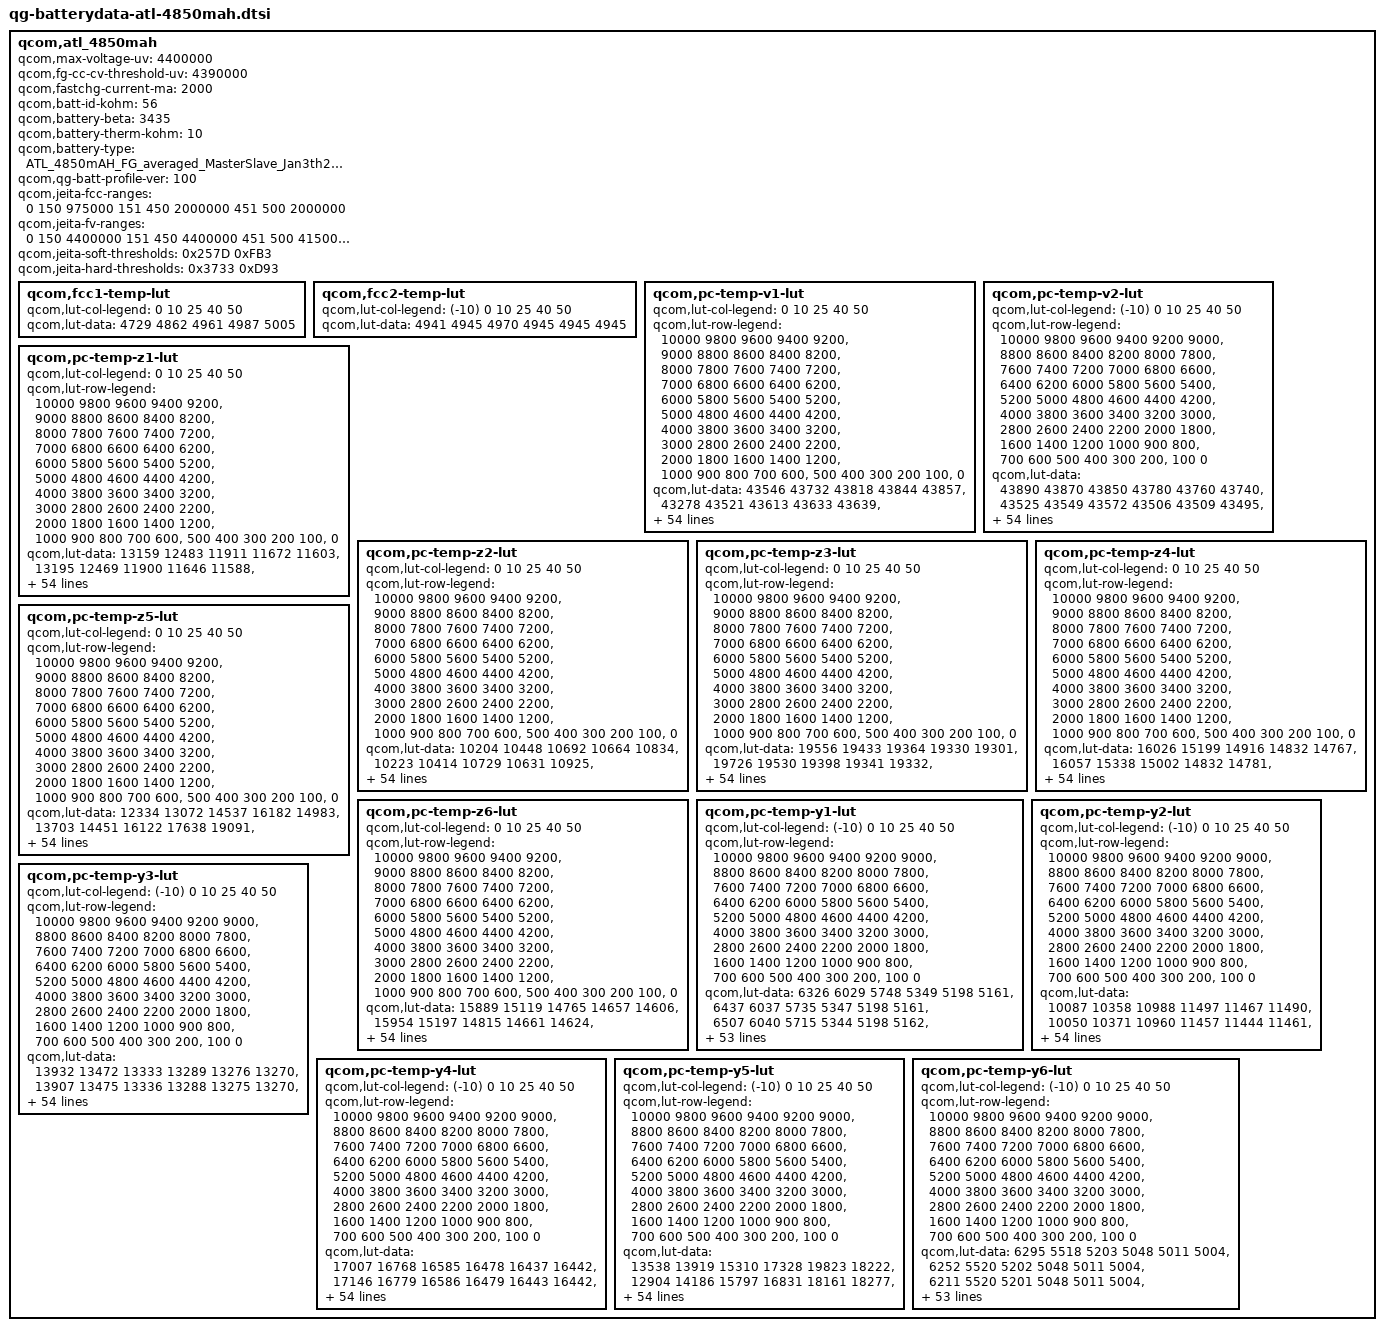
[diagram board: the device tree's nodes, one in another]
/* Copyright (c) 2018, The Linux Foundation. All rights reserved.
 *
 * This program is free software; you can redistribute it and/or modify
 * it under the terms of the GNU General Public License version 2 and
 * only version 2 as published by the Free Software Foundation.
 *
 * This program is distributed in the hope that it will be useful,
 * but WITHOUT ANY WARRANTY; without even the implied warranty of
 * MERCHANTABILITY or FITNESS FOR A PARTICULAR PURPOSE.  See the
 * GNU General Public License for more details.
 */

qcom,atl_4850mah {
    /* 3756981_LC_P400_ATL_4850mAH_FG_averaged_MasterSlave_Jan3th2019 */
    qcom,max-voltage-uv = <4400000>;
    qcom,fg-cc-cv-threshold-uv = <4390000>;
    qcom,fastchg-current-ma = <2000>;
    qcom,batt-id-kohm = <56>;
    qcom,battery-beta = <3435>;
    qcom,battery-therm-kohm = <10>;
    qcom,battery-type = "ATL_4850mAH_FG_averaged_MasterSlave_Jan3th2019";
    qcom,qg-batt-profile-ver = <100>;

	qcom,jeita-fcc-ranges = <0   150   975000
				151  450  2000000
				451  500  2000000>;
	qcom,jeita-fv-ranges =  <0   150  4400000
				151  450  4400000
				451  500  4150000>;

	/* COOL = 15 DegC, WARM = 45 DegC */
	qcom,jeita-soft-thresholds = <0x257D 0xFB3>;
	/* COLD = 0 DegC, HOT = 50 DegC */
	qcom,jeita-hard-thresholds = <0x3733 0xD93>;

	qcom,fcc1-temp-lut {
		qcom,lut-col-legend = <0 10 25 40 50>;
		qcom,lut-data = <4729 4862 4961 4987 5005>;
	};

	qcom,fcc2-temp-lut {
		qcom,lut-col-legend = <(-10) 0 10 25 40 50>;
		qcom,lut-data = <4941 4945 4970 4945 4945 4945>;
	};

	qcom,pc-temp-v1-lut {
		qcom,lut-col-legend = <0 10 25 40 50>;
		qcom,lut-row-legend = <10000 9800 9600 9400 9200>,
			<9000 8800 8600 8400 8200>,
			<8000 7800 7600 7400 7200>,
			<7000 6800 6600 6400 6200>,
			<6000 5800 5600 5400 5200>,
			<5000 4800 4600 4400 4200>,
			<4000 3800 3600 3400 3200>,
			<3000 2800 2600 2400 2200>,
			<2000 1800 1600 1400 1200>,
			<1000 900 800 700 600>,
			<500 400 300 200 100>,
			<0>;
		qcom,lut-data = <43546 43732 43818 43844 43857>,
			<43278 43521 43613 43633 43639>,
			<43030 43266 43386 43419 43438>,
			<42794 43019 43149 43197 43217>,
			<42564 42782 42912 42970 42990>,
			<42335 42546 42674 42734 42760>,
			<42109 42312 42437 42497 42528>,
			<41888 42080 42201 42265 42297>,
			<41669 41855 41969 42036 42066>,
			<41460 41633 41741 41809 41837>,
			<41273 41420 41515 41580 41609>,
			<41092 41223 41299 41357 41385>,
			<40884 41034 41097 41141 41166>,
			<40636 40827 40900 40932 40953>,
			<40395 40590 40690 40726 40746>,
			<40186 40361 40470 40523 40544>,
			<39993 40167 40267 40328 40349>,
			<39830 39990 40084 40145 40166>,
			<39696 39832 39912 39971 39990>,
			<39572 39698 39757 39806 39820>,
			<39444 39559 39614 39653 39662>,
			<39318 39391 39431 39474 39486>,
			<39191 39207 39153 39212 39247>,
			<39062 39021 38904 38960 39003>,
			<38935 38818 38770 38814 38844>,
			<38813 38655 38670 38711 38728>,
			<38694 38559 38579 38613 38621>,
			<38589 38488 38496 38515 38515>,
			<38494 38425 38419 38424 38417>,
			<38411 38370 38346 38338 38326>,
			<38351 38322 38279 38258 38243>,
			<38304 38276 38218 38188 38170>,
			<38265 38233 38162 38126 38107>,
			<38230 38195 38112 38070 38046>,
			<38200 38161 38071 38021 37988>,
			<38168 38126 38032 37975 37931>,
			<38136 38092 37993 37925 37869>,
			<38098 38054 37954 37873 37805>,
			<38040 37999 37900 37809 37733>,
			<37960 37908 37811 37723 37649>,
			<37865 37801 37701 37622 37553>,
			<37748 37681 37587 37513 37445>,
			<37613 37544 37458 37389 37319>,
			<37449 37387 37306 37238 37169>,
			<37317 37248 37165 37094 37026>,
			<37224 37154 37072 36998 36936>,
			<37195 37127 37047 36973 36911>,
			<37182 37111 37032 36956 36892>,
			<37154 37089 37014 36938 36875>,
			<37106 37044 36966 36902 36832>,
			<36893 36810 36729 36715 36615>,
			<36462 36384 36306 36328 36217>,
			<35905 35821 35745 35808 35691>,
			<35148 35053 34981 35116 34986>,
			<33972 33862 33814 34112 33949>,
			<30000 30000 30000 30000 30000>;
	};

	qcom,pc-temp-v2-lut {
		qcom,lut-col-legend = <(-10) 0 10 25 40 50>;
		qcom,lut-row-legend = <10000 9800 9600 9400 9200 9000>,
			<8800 8600 8400 8200 8000 7800>,
			<7600 7400 7200 7000 6800 6600>,
			<6400 6200 6000 5800 5600 5400>,
			<5200 5000 4800 4600 4400 4200>,
			<4000 3800 3600 3400 3200 3000>,
			<2800 2600 2400 2200 2000 1800>,
			<1600 1400 1200 1000 900 800>,
			<700 600 500 400 300 200>,
			<100 0>;
		qcom,lut-data = <43890 43870 43850 43780 43760 43740>,
			<43525 43549 43572 43506 43509 43495>,
			<43187 43249 43306 43243 43263 43255>,
			<42878 42974 43052 42993 43023 43018>,
			<42593 42723 42811 42756 42790 42787>,
			<42340 42477 42573 42521 42557 42555>,
			<42131 42228 42335 42287 42325 42323>,
			<41932 41987 42099 42054 42093 42091>,
			<41683 41766 41869 41826 41865 41862>,
			<41394 41559 41643 41602 41638 41635>,
			<41176 41352 41421 41381 41414 41412>,
			<41057 41140 41204 41162 41194 41194>,
			<40937 40930 40992 40947 40978 40980>,
			<40691 40741 40797 40744 40774 40774>,
			<40311 40562 40610 40548 40576 40572>,
			<39980 40333 40400 40349 40378 40376>,
			<39707 39994 40158 40137 40174 40183>,
			<39471 39671 39916 39938 39981 39998>,
			<39282 39469 39691 39778 39816 39830>,
			<39122 39309 39476 39636 39664 39669>,
			<38963 39145 39275 39450 39477 39479>,
			<38807 38977 39085 39190 39236 39242>,
			<38658 38819 38916 38951 39010 39019>,
			<38508 38677 38768 38784 38836 38843>,
			<38367 38545 38634 38645 38686 38689>,
			<38263 38408 38509 38523 38559 38562>,
			<38183 38260 38392 38416 38451 38454>,
			<38116 38142 38289 38319 38352 38355>,
			<38057 38065 38201 38229 38260 38262>,
			<38005 38004 38119 38146 38175 38175>,
			<37954 37953 38034 38072 38099 38097>,
			<37906 37912 37951 38003 38029 38026>,
			<37857 37871 37884 37939 37963 37959>,
			<37805 37828 37831 37876 37904 37899>,
			<37751 37784 37785 37816 37843 37837>,
			<37697 37739 37745 37754 37763 37747>,
			<37641 37694 37708 37690 37667 37628>,
			<37581 37642 37664 37624 37574 37520>,
			<37515 37581 37610 37554 37490 37427>,
			<37444 37512 37545 37480 37408 37341>,
			<37369 37433 37466 37404 37332 37263>,
			<37288 37339 37368 37319 37253 37186>,
			<37208 37230 37244 37211 37148 37081>,
			<37129 37112 37116 37077 37022 36954>,
			<37047 36994 36966 36931 36880 36818>,
			<36945 36884 36900 36880 36830 36774>,
			<36893 36841 36871 36869 36821 36761>,
			<36844 36797 36847 36852 36805 36747>,
			<36773 36747 36813 36825 36780 36726>,
			<36666 36670 36747 36763 36735 36673>,
			<36466 36509 36543 36550 36560 36463>,
			<36109 36149 36104 36110 36163 36052>,
			<35557 35597 35486 35524 35621 35500>,
			<34764 34800 34641 34732 34893 34767>,
			<33502 33572 33347 33535 33833 33689>,
			<30045 30824 29724 30182 32088 31980>;
	};

	qcom,pc-temp-z1-lut {
		qcom,lut-col-legend = <0 10 25 40 50>;
		qcom,lut-row-legend = <10000 9800 9600 9400 9200>,
			<9000 8800 8600 8400 8200>,
			<8000 7800 7600 7400 7200>,
			<7000 6800 6600 6400 6200>,
			<6000 5800 5600 5400 5200>,
			<5000 4800 4600 4400 4200>,
			<4000 3800 3600 3400 3200>,
			<3000 2800 2600 2400 2200>,
			<2000 1800 1600 1400 1200>,
			<1000 900 800 700 600>,
			<500 400 300 200 100>,
			<0>;
		qcom,lut-data = <13159 12483 11911 11672 11603>,
			<13195 12469 11900 11646 11588>,
			<13195 12465 11887 11641 11585>,
			<13186 12460 11870 11635 11581>,
			<13181 12453 11859 11630 11579>,
			<13187 12445 11852 11627 11576>,
			<13195 12431 11846 11624 11574>,
			<13193 12413 11840 11621 11573>,
			<13177 12408 11834 11619 11573>,
			<13167 12408 11832 11618 11573>,
			<13169 12407 11831 11619 11573>,
			<13173 12400 11831 11619 11574>,
			<13168 12384 11831 11619 11575>,
			<13127 12368 11832 11619 11576>,
			<13086 12348 11831 11619 11576>,
			<13071 12336 11830 11619 11576>,
			<13060 12338 11829 11618 11575>,
			<13059 12344 11830 11618 11575>,
			<13076 12351 11830 11618 11576>,
			<13093 12361 11832 11618 11576>,
			<13084 12368 11836 11621 11577>,
			<13055 12369 11839 11623 11578>,
			<13043 12369 11843 11624 11578>,
			<13057 12371 11847 11625 11579>,
			<13074 12377 11850 11627 11581>,
			<13078 12384 11853 11630 11583>,
			<13078 12388 11857 11633 11585>,
			<13079 12393 11863 11635 11588>,
			<13092 12398 11868 11637 11590>,
			<13109 12404 11874 11640 11593>,
			<13111 12411 11879 11644 11595>,
			<13107 12414 11883 11647 11597>,
			<13103 12418 11886 11650 11599>,
			<13107 12422 11890 11653 11601>,
			<13114 12426 11895 11656 11603>,
			<13119 12431 11900 11658 11605>,
			<13122 12437 11907 11661 11607>,
			<13125 12443 11914 11663 11610>,
			<13130 12451 11918 11665 11611>,
			<13136 12461 11919 11668 11613>,
			<13137 12468 11921 11670 11613>,
			<13130 12471 11925 11673 11615>,
			<13128 12472 11933 11676 11616>,
			<13149 12470 11937 11679 11619>,
			<13113 12473 11943 11681 11620>,
			<13170 12496 11947 11685 11621>,
			<13145 12484 11951 11686 11622>,
			<13157 12489 11952 11688 11623>,
			<13081 12501 11947 11689 11624>,
			<13093 12486 11954 11689 11625>,
			<13101 12521 11969 11693 11628>,
			<13112 12531 11972 11698 11633>,
			<13131 12538 11989 11708 11641>,
			<13225 12554 12072 11724 11654>,
			<13225 12554 12072 11724 11654>,
			<13225 12554 12072 11724 11654>;
	};

	qcom,pc-temp-z2-lut {
		qcom,lut-col-legend = <0 10 25 40 50>;
		qcom,lut-row-legend = <10000 9800 9600 9400 9200>,
			<9000 8800 8600 8400 8200>,
			<8000 7800 7600 7400 7200>,
			<7000 6800 6600 6400 6200>,
			<6000 5800 5600 5400 5200>,
			<5000 4800 4600 4400 4200>,
			<4000 3800 3600 3400 3200>,
			<3000 2800 2600 2400 2200>,
			<2000 1800 1600 1400 1200>,
			<1000 900 800 700 600>,
			<500 400 300 200 100>,
			<0>;
		qcom,lut-data = <10204 10448 10692 10664 10834>,
			<10223 10414 10729 10631 10925>,
			<10243 10386 10730 10919 10782>,
			<10263 10366 10700 10936 10924>,
			<10284 10352 10672 10939 11021>,
			<10308 10339 10641 10938 10994>,
			<10329 10323 10622 10936 10940>,
			<10330 10307 10619 10900 10894>,
			<10324 10298 10618 10808 10851>,
			<10316 10292 10618 10778 10797>,
			<10306 10289 10623 10812 10700>,
			<10294 10288 10631 10840 10621>,
			<10274 10288 10648 10837 10631>,
			<10233 10289 10665 10823 10674>,
			<10202 10299 10663 10793 10702>,
			<10198 10315 10652 10708 10715>,
			<10196 10337 10647 10656 10727>,
			<10197 10367 10664 10679 10739>,
			<10219 10397 10690 10720 10752>,
			<10240 10431 10712 10742 10778>,
			<10237 10457 10733 10757 10829>,
			<10226 10469 10739 10774 10857>,
			<10220 10477 10730 10802 10801>,
			<10219 10484 10718 10825 10724>,
			<10218 10491 10707 10815 10746>,
			<10220 10495 10695 10782 10874>,
			<10229 10497 10697 10771 10988>,
			<10238 10499 10726 10786 11082>,
			<10247 10498 10753 10813 11142>,
			<10256 10493 10766 10864 11080>,
			<10261 10488 10774 10931 10908>,
			<10264 10489 10775 10938 10793>,
			<10268 10490 10771 10885 10715>,
			<10273 10495 10769 10850 10677>,
			<10280 10511 10771 10863 10698>,
			<10290 10528 10776 10891 10749>,
			<10304 10536 10784 10921 10818>,
			<10321 10543 10801 10959 10926>,
			<10338 10551 10821 10996 10978>,
			<10355 10562 10851 11032 10977>,
			<10376 10571 10874 11061 10977>,
			<10397 10577 10874 11079 10980>,
			<10427 10583 10869 11090 10988>,
			<10479 10597 10864 11004 10962>,
			<10815 10713 10877 10957 10953>,
			<10922 10841 10971 11030 10989>,
			<10893 10830 10950 11037 10993>,
			<10789 10935 10981 10998 10991>,
			<10786 10956 10977 10978 10945>,
			<10767 11011 11013 11036 11179>,
			<10801 11037 11161 11181 10983>,
			<10657 11051 11145 11005 10711>,
			<10458 11013 11160 10963 10749>,
			<10162 10815 11138 10834 10720>,
			<10162 10815 11138 10834 10720>,
			<10162 10815 11138 10834 10720>;
	};

	qcom,pc-temp-z3-lut {
		qcom,lut-col-legend = <0 10 25 40 50>;
		qcom,lut-row-legend = <10000 9800 9600 9400 9200>,
			<9000 8800 8600 8400 8200>,
			<8000 7800 7600 7400 7200>,
			<7000 6800 6600 6400 6200>,
			<6000 5800 5600 5400 5200>,
			<5000 4800 4600 4400 4200>,
			<4000 3800 3600 3400 3200>,
			<3000 2800 2600 2400 2200>,
			<2000 1800 1600 1400 1200>,
			<1000 900 800 700 600>,
			<500 400 300 200 100>,
			<0>;
		qcom,lut-data = <19556 19433 19364 19330 19301>,
			<19726 19530 19398 19341 19332>,
			<19751 19580 19419 19366 19332>,
			<19756 19595 19431 19369 19344>,
			<19757 19599 19435 19373 19354>,
			<19734 19601 19436 19380 19357>,
			<19700 19603 19436 19384 19358>,
			<19688 19604 19437 19382 19358>,
			<19681 19604 19438 19375 19357>,
			<19678 19593 19437 19370 19355>,
			<19677 19580 19430 19368 19351>,
			<19676 19573 19422 19366 19346>,
			<19678 19566 19413 19363 19341>,
			<19698 19561 19405 19361 19337>,
			<19714 19558 19405 19357 19333>,
			<19708 19555 19409 19348 19331>,
			<19691 19542 19410 19343 19330>,
			<19673 19523 19405 19343 19328>,
			<19647 19511 19399 19343 19325>,
			<19628 19504 19398 19341 19323>,
			<19632 19500 19397 19337 19322>,
			<19649 19513 19398 19335 19320>,
			<19669 19539 19410 19340 19318>,
			<19693 19549 19421 19346 19316>,
			<19716 19552 19417 19342 19312>,
			<19725 19553 19408 19330 19308>,
			<19730 19552 19402 19326 19307>,
			<19732 19548 19399 19331 19329>,
			<19731 19545 19398 19338 19351>,
			<19729 19540 19401 19349 19352>,
			<19725 19535 19407 19362 19352>,
			<19714 19531 19411 19365 19350>,
			<19702 19528 19415 19362 19342>,
			<19691 19525 19416 19358 19334>,
			<19680 19523 19414 19353 19331>,
			<19668 19520 19411 19348 19329>,
			<19656 19515 19407 19346 19329>,
			<19646 19510 19403 19345 19328>,
			<19641 19505 19400 19344 19328>,
			<19638 19501 19398 19342 19326>,
			<19633 19498 19397 19342 19323>,
			<19615 19497 19395 19341 19323>,
			<19598 19495 19391 19340 19322>,
			<19589 19488 19386 19338 19320>,
			<19508 19461 19376 19331 19319>,
			<19466 19437 19369 19328 19313>,
			<19447 19433 19367 19325 19311>,
			<19317 19403 19353 19321 19312>,
			<19313 19403 19351 19321 19308>,
			<19309 19400 19348 19317 19298>,
			<19317 19400 19337 19311 19314>,
			<19316 19383 19324 19319 19325>,
			<19323 19338 19322 19318 19314>,
			<19329 19333 19319 19324 19312>,
			<19329 19333 19319 19324 19312>,
			<19329 19333 19319 19324 19312>;
	};

	qcom,pc-temp-z4-lut {
		qcom,lut-col-legend = <0 10 25 40 50>;
		qcom,lut-row-legend = <10000 9800 9600 9400 9200>,
			<9000 8800 8600 8400 8200>,
			<8000 7800 7600 7400 7200>,
			<7000 6800 6600 6400 6200>,
			<6000 5800 5600 5400 5200>,
			<5000 4800 4600 4400 4200>,
			<4000 3800 3600 3400 3200>,
			<3000 2800 2600 2400 2200>,
			<2000 1800 1600 1400 1200>,
			<1000 900 800 700 600>,
			<500 400 300 200 100>,
			<0>;
		qcom,lut-data = <16026 15199 14916 14832 14767>,
			<16057 15338 15002 14832 14781>,
			<16009 15264 14994 14855 14807>,
			<15833 15186 14938 14829 14792>,
			<15675 15095 14893 14802 14775>,
			<15574 15011 14855 14779 14759>,
			<15487 14949 14822 14759 14743>,
			<15409 14897 14795 14745 14729>,
			<15341 14861 14771 14735 14718>,
			<15279 14834 14751 14724 14708>,
			<15222 14813 14734 14711 14700>,
			<15171 14793 14722 14699 14694>,
			<15128 14775 14717 14690 14688>,
			<15090 14764 14713 14683 14684>,
			<15058 14757 14709 14680 14679>,
			<15031 14752 14703 14680 14672>,
			<15008 14748 14697 14679 14666>,
			<14989 14746 14688 14670 14659>,
			<14974 14740 14680 14658 14653>,
			<14958 14726 14674 14657 14652>,
			<14928 14716 14670 14658 14653>,
			<14883 14716 14674 14662 14654>,
			<14844 14716 14736 14718 14704>,
			<14807 14722 14790 14779 14770>,
			<14780 14766 14790 14784 14778>,
			<14777 14800 14787 14783 14775>,
			<14777 14795 14782 14781 14769>,
			<14777 14784 14771 14765 14736>,
			<14780 14773 14757 14743 14698>,
			<14784 14763 14741 14718 14682>,
			<14784 14752 14723 14692 14672>,
			<14781 14742 14709 14679 14666>,
			<14778 14732 14697 14672 14661>,
			<14775 14723 14690 14668 14659>,
			<14771 14715 14687 14667 14659>,
			<14768 14709 14685 14666 14658>,
			<14764 14704 14684 14667 14659>,
			<14759 14699 14682 14671 14666>,
			<14750 14699 14682 14675 14672>,
			<14739 14702 14687 14682 14678>,
			<14735 14704 14692 14687 14683>,
			<14738 14700 14689 14684 14680>,
			<14739 14694 14683 14675 14673>,
			<14723 14692 14683 14678 14676>,
			<14724 14683 14678 14677 14675>,
			<14731 14672 14655 14660 14661>,
			<14752 14670 14651 14655 14656>,
			<14892 14696 14654 14646 14640>,
			<14889 14689 14648 14630 14628>,
			<14885 14689 14650 14630 14631>,
			<14875 14693 14678 14658 14638>,
			<14895 14721 14698 14657 14636>,
			<14901 14780 14703 14659 14647>,
			<14913 14794 14707 14654 14648>,
			<14913 14794 14707 14654 14648>,
			<14913 14794 14707 14654 14648>;
	};

	qcom,pc-temp-z5-lut {
		qcom,lut-col-legend = <0 10 25 40 50>;
		qcom,lut-row-legend = <10000 9800 9600 9400 9200>,
			<9000 8800 8600 8400 8200>,
			<8000 7800 7600 7400 7200>,
			<7000 6800 6600 6400 6200>,
			<6000 5800 5600 5400 5200>,
			<5000 4800 4600 4400 4200>,
			<4000 3800 3600 3400 3200>,
			<3000 2800 2600 2400 2200>,
			<2000 1800 1600 1400 1200>,
			<1000 900 800 700 600>,
			<500 400 300 200 100>,
			<0>;
		qcom,lut-data = <12334 13072 14537 16182 14983>,
			<13703 14451 16122 17638 19091>,
			<14086 15751 16917 19065 17988>,
			<14259 16545 17527 19156 19262>,
			<14312 16964 17982 19337 20357>,
			<14314 17379 18294 20322 20699>,
			<14316 18155 18649 21287 20917>,
			<14347 19089 19267 21036 21023>,
			<14495 19507 20019 20175 21080>,
			<14666 19630 20648 19937 21157>,
			<14794 19764 21254 20749 21349>,
			<14934 20078 21510 21787 21515>,
			<15195 20605 21050 22625 21434>,
			<15784 21369 20445 23354 21190>,
			<16200 22837 20553 23248 21144>,
			<16129 23839 21335 21671 21661>,
			<15914 22893 22243 20636 22472>,
			<15693 20986 23150 22232 23607>,
			<15414 20525 24310 24653 24985>,
			<15214 21176 25936 25226 25766>,
			<15554 22461 28333 25337 26288>,
			<16899 31858 32351 25590 26494>,
			<18826 47923 42607 27668 25105>,
			<22724 52013 50310 29850 22508>,
			<27674 51824 45424 27661 19977>,
			<31966 51448 34272 21089 17142>,
			<36191 48668 28530 18631 16194>,
			<39048 43301 25504 18522 18374>,
			<40729 39535 24205 18478 21576>,
			<41825 36523 24851 20231 24388>,
			<41535 34944 26450 24460 27085>,
			<38750 34816 28879 27721 27739>,
			<35546 34754 33247 30409 27573>,
			<33024 34848 36667 32326 27446>,
			<30672 35518 38739 33560 29539>,
			<29018 36005 40045 34367 33039>,
			<27654 35801 39769 34429 33658>,
			<26896 35305 38222 34212 33468>,
			<27835 34716 36659 33784 33081>,
			<30145 33833 35300 31128 29459>,
			<30873 33321 33943 28027 24902>,
			<28325 33747 32709 27243 23793>,
			<27052 34231 31392 26858 23345>,
			<30100 32416 28490 24774 21938>,
			<25102 30006 27193 23395 21517>,
			<20681 27928 29321 24400 21102>,
			<19350 26586 28192 23276 20571>,
			<12461 18931 22374 23125 23053>,
			<12394 19245 22060 26559 25040>,
			<12392 19076 21681 25139 20585>,
			<12645 19416 17699 17955 20893>,
			<12433 16375 15306 17613 21564>,
			<12338 13458 14723 16830 17428>,
			<12189 13023 14264 17361 16332>,
			<12189 13023 14264 17361 16332>,
			<12189 13023 14264 17361 16332>;
	};

	qcom,pc-temp-z6-lut {
		qcom,lut-col-legend = <0 10 25 40 50>;
		qcom,lut-row-legend = <10000 9800 9600 9400 9200>,
			<9000 8800 8600 8400 8200>,
			<8000 7800 7600 7400 7200>,
			<7000 6800 6600 6400 6200>,
			<6000 5800 5600 5400 5200>,
			<5000 4800 4600 4400 4200>,
			<4000 3800 3600 3400 3200>,
			<3000 2800 2600 2400 2200>,
			<2000 1800 1600 1400 1200>,
			<1000 900 800 700 600>,
			<500 400 300 200 100>,
			<0>;
		qcom,lut-data = <15889 15119 14765 14657 14606>,
			<15954 15197 14815 14661 14624>,
			<15933 15183 14815 14682 14636>,
			<15838 15162 14796 14673 14635>,
			<15745 15116 14778 14664 14634>,
			<15674 15068 14760 14657 14630>,
			<15610 15036 14745 14650 14623>,
			<15560 15010 14733 14643 14617>,
			<15520 14986 14722 14635 14611>,
			<15486 14965 14712 14627 14606>,
			<15455 14947 14701 14620 14600>,
			<15428 14932 14691 14614 14595>,
			<15407 14920 14684 14609 14590>,
			<15390 14910 14678 14604 14585>,
			<15373 14900 14675 14600 14581>,
			<15353 14891 14674 14596 14577>,
			<15331 14881 14673 14592 14573>,
			<15310 14871 14666 14587 14569>,
			<15290 14862 14659 14582 14565>,
			<15273 14854 14656 14581 14563>,
			<15260 14850 14655 14580 14563>,
			<15249 14855 14657 14580 14562>,
			<15245 14869 14691 14607 14582>,
			<15246 14885 14720 14637 14610>,
			<15248 14906 14719 14638 14612>,
			<15250 14919 14714 14633 14610>,
			<15252 14917 14709 14628 14607>,
			<15255 14912 14704 14624 14604>,
			<15258 14907 14699 14620 14600>,
			<15260 14902 14694 14616 14596>,
			<15259 14897 14690 14612 14592>,
			<15253 14891 14687 14608 14587>,
			<15246 14887 14685 14604 14581>,
			<15242 14883 14683 14600 14576>,
			<15237 14881 14681 14597 14574>,
			<15233 14878 14680 14594 14573>,
			<15228 14875 14678 14594 14573>,
			<15224 14872 14676 14595 14576>,
			<15222 14872 14675 14596 14578>,
			<15220 14874 14677 14599 14579>,
			<15216 14876 14679 14601 14580>,
			<15208 14877 14678 14599 14579>,
			<15200 14877 14675 14596 14576>,
			<15196 14876 14673 14595 14576>,
			<15159 14862 14668 14593 14576>,
			<15144 14849 14656 14584 14567>,
			<15142 14846 14653 14581 14563>,
			<15134 14843 14648 14575 14557>,
			<15130 14840 14644 14568 14550>,
			<15133 14842 14645 14566 14546>,
			<15141 14848 14653 14575 14558>,
			<15156 14856 14657 14581 14564>,
			<15174 14869 14662 14584 14566>,
			<15204 14886 14669 14587 14568>,
			<15204 14886 14669 14587 14568>,
			<15204 14886 14669 14587 14568>;
	};

	qcom,pc-temp-y1-lut {
		qcom,lut-col-legend = <(-10) 0 10 25 40 50>;
		qcom,lut-row-legend = <10000 9800 9600 9400 9200 9000>,
			<8800 8600 8400 8200 8000 7800>,
			<7600 7400 7200 7000 6800 6600>,
			<6400 6200 6000 5800 5600 5400>,
			<5200 5000 4800 4600 4400 4200>,
			<4000 3800 3600 3400 3200 3000>,
			<2800 2600 2400 2200 2000 1800>,
			<1600 1400 1200 1000 900 800>,
			<700 600 500 400 300 200>,
			<100 0>;
		qcom,lut-data = <6326 6029 5748 5349 5198 5161>,
			<6437 6037 5735 5347 5198 5161>,
			<6507 6040 5715 5344 5198 5162>,
			<6545 6040 5693 5342 5197 5162>,
			<6562 6037 5676 5339 5196 5162>,
			<6565 6033 5668 5337 5195 5162>,
			<6531 6024 5666 5334 5193 5161>,
			<6488 6015 5665 5331 5191 5160>,
			<6484 6016 5663 5330 5191 5159>,
			<6487 6026 5661 5329 5191 5159>,
			<6491 6030 5658 5328 5192 5159>,
			<6499 6019 5654 5325 5191 5158>,
			<6507 6007 5650 5323 5189 5157>,
			<6510 6007 5647 5322 5188 5157>,
			<6513 6010 5645 5321 5188 5157>,
			<6512 6015 5643 5321 5188 5157>,
			<6500 6031 5640 5322 5189 5158>,
			<6489 6043 5639 5324 5189 5159>,
			<6495 6038 5640 5324 5189 5159>,
			<6507 6028 5642 5324 5189 5159>,
			<6508 6025 5643 5325 5189 5159>,
			<6495 6031 5643 5328 5189 5159>,
			<6485 6036 5643 5331 5190 5158>,
			<6490 6034 5646 5334 5191 5159>,
			<6500 6030 5651 5337 5193 5162>,
			<6502 6030 5655 5340 5195 5162>,
			<6499 6037 5658 5344 5195 5163>,
			<6496 6042 5662 5347 5196 5163>,
			<6494 6043 5673 5351 5199 5165>,
			<6493 6043 5681 5354 5203 5168>,
			<6488 6048 5682 5358 5205 5170>,
			<6473 6062 5682 5363 5206 5171>,
			<6465 6068 5683 5367 5208 5173>,
			<6473 6046 5690 5370 5211 5174>,
			<6483 6021 5695 5374 5215 5176>,
			<6484 6022 5693 5377 5217 5178>,
			<6483 6034 5689 5380 5220 5180>,
			<6482 6038 5688 5383 5222 5181>,
			<6468 6035 5690 5390 5223 5182>,
			<6452 6031 5693 5395 5224 5183>,
			<6459 6041 5707 5395 5225 5184>,
			<6474 6059 5718 5394 5225 5185>,
			<6476 6042 5710 5401 5227 5185>,
			<6490 6030 5709 5407 5228 5186>,
			<6501 6051 5715 5412 5232 5190>,
			<6464 6029 5716 5411 5233 5192>,
			<6458 6053 5718 5425 5236 5191>,
			<6527 6042 5713 5418 5235 5191>,
			<6474 6075 5740 5426 5237 5193>,
			<6532 6077 5735 5423 5237 5193>,
			<6488 6032 5723 5435 5237 5194>,
			<6533 6076 5724 5436 5241 5198>,
			<6624 6088 5730 5457 5249 5203>,
			<6618 6126 5756 5472 5260 5211>,
			<6618 6126 5756 5472 5260 5211>,
			<6618 6126 5756 5472 5260 5211>;
	};

	qcom,pc-temp-y2-lut {
		qcom,lut-col-legend = <(-10) 0 10 25 40 50>;
		qcom,lut-row-legend = <10000 9800 9600 9400 9200 9000>,
			<8800 8600 8400 8200 8000 7800>,
			<7600 7400 7200 7000 6800 6600>,
			<6400 6200 6000 5800 5600 5400>,
			<5200 5000 4800 4600 4400 4200>,
			<4000 3800 3600 3400 3200 3000>,
			<2800 2600 2400 2200 2000 1800>,
			<1600 1400 1200 1000 900 800>,
			<700 600 500 400 300 200>,
			<100 0>;
		qcom,lut-data = <10087 10358 10988 11497 11467 11490>,
			<10050 10371 10960 11457 11444 11461>,
			<10040 10388 10933 11408 11422 11426>,
			<10052 10407 10907 11358 11401 11391>,
			<10078 10429 10885 11318 11383 11363>,
			<10114 10453 10870 11296 11369 11347>,
			<10161 10487 10857 11288 11358 11341>,
			<10228 10516 10849 11282 11350 11336>,
			<10358 10512 10854 11269 11364 11317>,
			<10580 10490 10871 11250 11410 11279>,
			<10667 10488 10878 11243 11430 11266>,
			<10583 10672 10876 11255 11406 11322>,
			<10493 10866 10874 11267 11369 11381>,
			<10528 10878 10904 11262 11329 11357>,
			<10658 10876 10987 11248 11284 11284>,
			<10772 10874 11059 11248 11278 11261>,
			<10877 10873 11129 11316 11392 11297>,
			<10942 10873 11168 11401 11545 11362>,
			<10642 10890 11158 11460 11683 11503>,
			<9972 10936 11142 11509 11814 11702>,
			<9745 10986 11145 11512 11837 11740>,
			<9715 11048 11180 11458 11771 11637>,
			<9700 11100 11213 11417 11689 11546>,
			<9691 11132 11229 11427 11608 11522>,
			<9685 11155 11242 11452 11535 11507>,
			<9681 11156 11265 11478 11530 11513>,
			<9678 11143 11299 11507 11574 11560>,
			<9676 11134 11319 11539 11621 11619>,
			<9674 11133 11327 11579 11651 11674>,
			<9672 11133 11332 11614 11680 11738>,
			<9671 11127 11334 11623 11718 11831>,
			<9669 11097 11335 11627 11765 11964>,
			<9667 11036 11335 11628 11805 12022>,
			<9666 10529 11331 11620 11839 11998>,
			<9665 9926 11324 11606 11861 11951>,
			<9664 9777 11308 11583 11851 11859>,
			<9663 9711 11281 11548 11805 11700>,
			<9663 9687 11253 11528 11753 11642>,
			<9662 9680 11224 11521 11681 11676>,
			<9661 9676 11194 11516 11629 11709>,
			<9661 9672 11165 11512 11653 11671>,
			<9661 9668 11128 11508 11701 11600>,
			<9660 9665 11060 11491 11680 11617>,
			<9660 9662 10999 11464 11674 11702>,
			<9659 9662 10631 11401 11690 11707>,
			<9659 9660 10822 11394 11521 11517>,
			<9658 9659 10779 11399 11569 11423>,
			<9658 9658 10730 11387 11479 11368>,
			<9658 9658 10688 11367 11530 11464>,
			<9658 9657 10657 11365 11511 11379>,
			<9656 9657 10584 11325 11471 11323>,
			<9654 9656 10159 11239 11370 11272>,
			<9653 9655 9683 11164 11348 11196>,
			<9651 9653 9670 11064 11241 11042>,
			<9651 9653 9670 11064 11241 11042>,
			<9651 9653 9670 11064 11241 11042>;
	};

	qcom,pc-temp-y3-lut {
		qcom,lut-col-legend = <(-10) 0 10 25 40 50>;
		qcom,lut-row-legend = <10000 9800 9600 9400 9200 9000>,
			<8800 8600 8400 8200 8000 7800>,
			<7600 7400 7200 7000 6800 6600>,
			<6400 6200 6000 5800 5600 5400>,
			<5200 5000 4800 4600 4400 4200>,
			<4000 3800 3600 3400 3200 3000>,
			<2800 2600 2400 2200 2000 1800>,
			<1600 1400 1200 1000 900 800>,
			<700 600 500 400 300 200>,
			<100 0>;
		qcom,lut-data = <13932 13472 13333 13289 13276 13270>,
			<13907 13475 13336 13288 13275 13270>,
			<13857 13477 13340 13287 13274 13271>,
			<13799 13477 13343 13287 13274 13272>,
			<13753 13476 13346 13287 13275 13272>,
			<13736 13474 13348 13287 13275 13273>,
			<13738 13469 13349 13287 13278 13274>,
			<13740 13465 13349 13288 13281 13275>,
			<13725 13469 13350 13290 13282 13275>,
			<13666 13486 13350 13294 13283 13275>,
			<13605 13493 13350 13296 13283 13276>,
			<13540 13472 13349 13297 13283 13278>,
			<13494 13446 13347 13297 13283 13280>,
			<13497 13435 13349 13299 13283 13281>,
			<13513 13427 13352 13302 13283 13281>,
			<13516 13422 13352 13302 13283 13281>,
			<13480 13419 13350 13300 13284 13279>,
			<13439 13415 13346 13298 13285 13278>,
			<13420 13406 13342 13300 13285 13280>,
			<13407 13392 13338 13303 13286 13283>,
			<13405 13383 13333 13303 13286 13284>,
			<13413 13377 13329 13297 13283 13280>,
			<13419 13371 13325 13292 13280 13276>,
			<13411 13364 13324 13289 13278 13273>,
			<13396 13356 13322 13287 13277 13271>,
			<13389 13348 13320 13287 13276 13271>,
			<13385 13341 13316 13287 13276 13273>,
			<13384 13335 13314 13288 13276 13274>,
			<13397 13331 13316 13289 13276 13273>,
			<13422 13328 13317 13290 13276 13272>,
			<13444 13329 13317 13290 13276 13272>,
			<13465 13334 13315 13292 13276 13272>,
			<13487 13338 13314 13292 13277 13273>,
			<13510 13339 13313 13292 13278 13273>,
			<13535 13341 13313 13291 13278 13274>,
			<13565 13343 13314 13291 13278 13274>,
			<13599 13344 13317 13290 13277 13273>,
			<13636 13348 13319 13289 13276 13272>,
			<13679 13362 13320 13288 13276 13271>,
			<13724 13386 13321 13287 13275 13271>,
			<13761 13416 13322 13288 13276 13272>,
			<13796 13456 13323 13289 13276 13273>,
			<13846 13508 13321 13290 13276 13274>,
			<13901 13571 13322 13289 13276 13273>,
			<13879 13567 13307 13284 13273 13271>,
			<13940 13656 13326 13287 13275 13273>,
			<14007 13727 13328 13291 13279 13274>,
			<14079 13797 13336 13293 13279 13277>,
			<14148 13867 13344 13297 13281 13282>,
			<14239 13931 13354 13300 13286 13283>,
			<14427 13994 13360 13299 13282 13279>,
			<14742 14072 13359 13297 13281 13276>,
			<15342 14274 13386 13303 13284 13278>,
			<16418 14696 13524 13310 13285 13283>,
			<16418 14696 13524 13310 13285 13283>,
			<16418 14696 13524 13310 13285 13283>;
	};

	qcom,pc-temp-y4-lut {
		qcom,lut-col-legend = <(-10) 0 10 25 40 50>;
		qcom,lut-row-legend = <10000 9800 9600 9400 9200 9000>,
			<8800 8600 8400 8200 8000 7800>,
			<7600 7400 7200 7000 6800 6600>,
			<6400 6200 6000 5800 5600 5400>,
			<5200 5000 4800 4600 4400 4200>,
			<4000 3800 3600 3400 3200 3000>,
			<2800 2600 2400 2200 2000 1800>,
			<1600 1400 1200 1000 900 800>,
			<700 600 500 400 300 200>,
			<100 0>;
		qcom,lut-data = <17007 16768 16585 16478 16437 16442>,
			<17146 16779 16586 16479 16443 16442>,
			<17230 16798 16586 16480 16447 16441>,
			<17272 16820 16586 16481 16450 16441>,
			<17287 16837 16586 16483 16451 16441>,
			<17288 16843 16586 16485 16452 16441>,
			<17226 16843 16585 16488 16450 16442>,
			<17149 16841 16583 16491 16448 16444>,
			<17143 16835 16585 16491 16448 16446>,
			<17156 16818 16592 16491 16452 16450>,
			<17184 16813 16601 16492 16456 16452>,
			<17352 16873 16609 16497 16462 16453>,
			<17522 16953 16622 16506 16468 16454>,
			<17428 17001 16657 16516 16476 16457>,
			<17127 17040 16711 16528 16484 16464>,
			<16963 17037 16725 16542 16492 16472>,
			<16902 16868 16714 16560 16500 16480>,
			<16872 16717 16696 16578 16509 16490>,
			<16884 16715 16656 16596 16528 16503>,
			<16913 16719 16599 16614 16551 16516>,
			<16916 16718 16566 16609 16553 16517>,
			<16868 16698 16544 16543 16516 16495>,
			<16814 16674 16531 16487 16479 16472>,
			<16778 16661 16524 16475 16462 16458>,
			<16750 16648 16520 16469 16450 16447>,
			<16746 16625 16520 16468 16448 16446>,
			<16751 16581 16521 16469 16450 16446>,
			<16755 16557 16522 16469 16453 16447>,
			<16749 16561 16522 16472 16458 16452>,
			<16741 16565 16521 16477 16466 16460>,
			<16738 16566 16516 16483 16473 16468>,
			<16737 16567 16505 16490 16482 16476>,
			<16736 16568 16501 16495 16490 16483>,
			<16741 16590 16504 16497 16497 16492>,
			<16748 16623 16509 16499 16502 16498>,
			<16748 16645 16515 16497 16496 16491>,
			<16745 16662 16522 16488 16476 16468>,
			<16742 16672 16530 16481 16462 16454>,
			<16740 16676 16539 16474 16454 16449>,
			<16739 16679 16544 16469 16450 16446>,
			<16740 16676 16546 16472 16453 16449>,
			<16744 16668 16547 16477 16459 16454>,
			<16757 16665 16546 16479 16458 16453>,
			<16764 16661 16542 16479 16455 16449>,
			<16741 16645 16547 16469 16442 16435>,
			<16750 16655 16536 16472 16446 16440>,
			<16765 16668 16550 16479 16451 16448>,
			<16781 16691 16570 16489 16462 16457>,
			<16799 16727 16601 16505 16473 16472>,
			<16815 16766 16640 16522 16491 16491>,
			<16855 16791 16646 16511 16476 16459>,
			<16930 16758 16671 16497 16453 16446>,
			<17106 16781 16723 16507 16450 16445>,
			<17541 16947 16712 16529 16457 16448>,
			<17541 16947 16712 16529 16457 16448>,
			<17541 16947 16712 16529 16457 16448>;
	};

	qcom,pc-temp-y5-lut {
		qcom,lut-col-legend = <(-10) 0 10 25 40 50>;
		qcom,lut-row-legend = <10000 9800 9600 9400 9200 9000>,
			<8800 8600 8400 8200 8000 7800>,
			<7600 7400 7200 7000 6800 6600>,
			<6400 6200 6000 5800 5600 5400>,
			<5200 5000 4800 4600 4400 4200>,
			<4000 3800 3600 3400 3200 3000>,
			<2800 2600 2400 2200 2000 1800>,
			<1600 1400 1200 1000 900 800>,
			<700 600 500 400 300 200>,
			<100 0>;
		qcom,lut-data = <13538 13919 15310 17328 19823 18222>,
			<12904 14186 15797 16831 18161 18277>,
			<12624 14638 16571 16332 17165 18302>,
			<12633 15137 17396 15866 16664 18301>,
			<12866 15542 18034 15473 16488 18278>,
			<13275 15716 18251 15188 16485 18238>,
			<15147 15738 18213 14959 17908 18059>,
			<17242 15757 18126 14811 19691 17749>,
			<16883 16472 17907 15052 19722 17318>,
			<14859 18760 17409 15905 19042 16708>,
			<13960 19667 16912 16270 18289 16512>,
			<14409 17195 16354 15975 17500 17476>,
			<15336 14579 15985 15575 16688 18494>,
			<17826 15955 16035 15330 15879 18241>,
			<22392 20046 16272 15132 15094 17243>,
			<23714 21585 16998 15082 14875 16315>,
			<20177 21684 20424 15149 14963 15362>,
			<16401 21725 23159 15294 15127 14770>,
			<15171 20923 23514 17112 15425 15086>,
			<14408 19234 23700 20667 16010 16050>,
			<14298 18844 23491 21612 17194 17345>,
			<14691 19465 22241 21439 20549 19650>,
			<14997 20189 21484 21135 22832 21100>,
			<14406 20776 21513 20151 22311 20075>,
			<13256 21265 21552 18814 21227 18308>,
			<12732 20977 21126 18639 20524 18195>,
			<12469 18814 19539 19189 20052 19540>,
			<12365 16916 18862 19869 19609 20365>,
			<12529 15950 20769 20516 19044 19171>,
			<12837 15320 22846 21253 18585 17493>,
			<13080 15497 22883 22172 18588 17279>,
			<13315 16482 22508 23327 18904 17417>,
			<13410 16953 22028 24157 19388 17652>,
			<13342 15834 21201 24696 20660 18503>,
			<13257 14449 20618 25023 21926 19526>,
			<13328 14157 21264 24792 22125 20006>,
			<13602 14041 22594 23820 22185 20330>,
			<13750 14018 22894 22696 22178 20393>,
			<13783 14149 22585 21099 21722 19829>,
			<13799 14331 22193 19926 21032 19268>,
			<13670 14479 21898 20031 20352 19425>,
			<13341 14589 21448 20320 19711 19793>,
			<13123 14332 19367 20073 19461 19886>,
			<13138 14200 19275 19360 19288 19610>,
			<13445 14037 14685 17259 18543 20295>,
			<13196 13708 18741 17626 18088 18446>,
			<13290 13944 17943 19162 19291 17003>,
			<13821 14016 18475 18532 17343 18262>,
			<14013 14263 18775 18288 17549 20232>,
			<14474 14502 19380 18672 18986 19048>,
			<14102 14573 18882 18563 17460 18733>,
			<12892 14381 16472 18278 18840 17489>,
			<11415 13639 13799 19860 21786 18379>,
			<10465 11883 14330 20989 21110 23747>,
			<10465 11883 14330 20989 21110 23747>,
			<10465 11883 14330 20989 21110 23747>;
	};

	qcom,pc-temp-y6-lut {
		qcom,lut-col-legend = <(-10) 0 10 25 40 50>;
		qcom,lut-row-legend = <10000 9800 9600 9400 9200 9000>,
			<8800 8600 8400 8200 8000 7800>,
			<7600 7400 7200 7000 6800 6600>,
			<6400 6200 6000 5800 5600 5400>,
			<5200 5000 4800 4600 4400 4200>,
			<4000 3800 3600 3400 3200 3000>,
			<2800 2600 2400 2200 2000 1800>,
			<1600 1400 1200 1000 900 800>,
			<700 600 500 400 300 200>,
			<100 0>;
		qcom,lut-data = <6295 5518 5203 5048 5011 5004>,
			<6252 5520 5202 5048 5011 5004>,
			<6211 5520 5201 5048 5011 5004>,
			<6172 5518 5199 5048 5012 5004>,
			<6138 5514 5197 5048 5012 5005>,
			<6108 5509 5195 5048 5013 5005>,
			<6084 5501 5192 5048 5014 5006>,
			<6061 5494 5189 5049 5016 5007>,
			<6031 5493 5189 5051 5017 5008>,
			<5995 5494 5189 5053 5018 5009>,
			<5982 5494 5189 5055 5020 5010>,
			<5986 5494 5189 5057 5021 5012>,
			<5991 5494 5190 5059 5023 5014>,
			<5971 5497 5197 5063 5025 5016>,
			<5911 5504 5213 5068 5028 5018>,
			<5864 5504 5217 5073 5030 5019>,
			<5830 5460 5213 5077 5033 5021>,
			<5808 5418 5205 5080 5036 5023>,
			<5802 5410 5191 5086 5042 5028>,
			<5798 5407 5172 5093 5049 5034>,
			<5794 5402 5160 5092 5049 5034>,
			<5789 5395 5150 5069 5036 5025>,
			<5784 5390 5144 5049 5023 5015>,
			<5779 5389 5142 5044 5017 5009>,
			<5776 5389 5141 5042 5012 5005>,
			<5777 5386 5141 5041 5012 5004>,
			<5791 5381 5141 5042 5012 5005>,
			<5808 5378 5141 5044 5013 5007>,
			<5827 5386 5144 5046 5015 5008>,
			<5848 5401 5148 5048 5017 5010>,
			<5868 5416 5148 5051 5020 5012>,
			<5887 5434 5147 5054 5023 5014>,
			<5908 5454 5147 5057 5025 5017>,
			<5934 5474 5150 5058 5028 5020>,
			<5962 5496 5155 5059 5031 5022>,
			<5989 5523 5162 5059 5029 5020>,
			<6018 5555 5171 5056 5022 5013>,
			<6048 5590 5181 5054 5018 5009>,
			<6084 5629 5190 5053 5016 5007>,
			<6119 5670 5201 5051 5014 5006>,
			<6149 5716 5212 5053 5016 5008>,
			<6178 5767 5224 5056 5018 5010>,
			<6221 5825 5237 5059 5018 5010>,
			<6269 5887 5255 5059 5017 5009>,
			<6256 5884 5244 5054 5012 5004>,
			<6305 5965 5282 5058 5015 5007>,
			<6361 6030 5304 5064 5019 5010>,
			<6421 6090 5334 5070 5022 5015>,
			<6480 6157 5371 5078 5027 5023>,
			<6557 6219 5413 5086 5036 5029>,
			<6739 6277 5442 5083 5029 5017>,
			<7052 6334 5486 5081 5021 5012>,
			<7638 6525 5582 5094 5024 5013>,
			<8647 6973 5741 5111 5028 5019>,
			<8647 6973 5741 5111 5028 5019>,
			<8647 6973 5741 5111 5028 5019>;
	};

};
